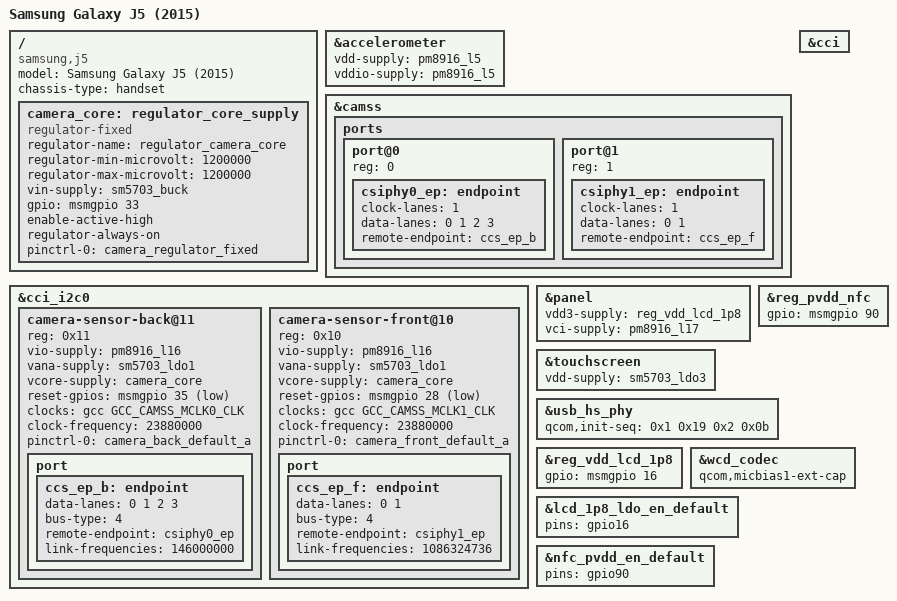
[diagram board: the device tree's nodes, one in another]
// SPDX-License-Identifier: GPL-2.0-only

/dts-v1/;

#include "msm8916-samsung-j5-common.dtsi"

/ {
	model = "Samsung Galaxy J5 (2015)";
	compatible = "samsung,j5", "qcom,msm8916";
	chassis-type = "handset";

	camera_core: regulator_core_supply {
		compatible = "regulator-fixed";
		regulator-name = "regulator_camera_core";
		regulator-min-microvolt = <1200000>;
		regulator-max-microvolt = <1200000>;

		vin-supply = <&sm5703_buck>;

		gpio = <&msmgpio 33 GPIO_ACTIVE_HIGH>;
		enable-active-high;
		regulator-always-on;

		pinctrl-names = "default";
		pinctrl-0 = <&camera_regulator_fixed>;
	};
};

&accelerometer {
	vdd-supply = <&pm8916_l5>;
	vddio-supply = <&pm8916_l5>;
};

&camss {
	status = "okay";

	ports {
		port@0 {
			reg = <0>;
			csiphy0_ep: endpoint {
				clock-lanes = <1>;
				data-lanes = <0 1 2 3>;
				remote-endpoint = <&ccs_ep_b>;
			};
		};
		port@1 {
			reg = <1>;
			csiphy1_ep: endpoint {
				clock-lanes = <1>;
				data-lanes = <0 1>;
				remote-endpoint = <&ccs_ep_f>;
			};
		};
	};
};

&cci {
	status = "okay";
};

// link-freq = width * height * bpp * fps / (2 * nlanes)

&cci_i2c0 {
	#address-cells = <1>;
	#size-cells = <0>;

	camera-sensor-back@11 {
		reg = <0x11>;
		// compatible = "mipi-ccs-1.0", "mipi-ccs";
		vio-supply = <&pm8916_l16>;
		vana-supply = <&sm5703_ldo1>;
		vcore-supply = <&camera_core>;
		reset-gpios = <&msmgpio 35 GPIO_ACTIVE_LOW>;
		clocks = <&gcc GCC_CAMSS_MCLK0_CLK>;
		clock-frequency = <23880000>;
		pinctrl-names = "default";
		pinctrl-0 = <&camera_back_default_a>;
		port {
			ccs_ep_b: endpoint {
				data-lanes = <0 1 2 3>;
				bus-type = <4>;
				remote-endpoint = <&csiphy0_ep>;
				link-frequencies = /bits/ 64 <146000000>;
			};
		};
	};

	camera-sensor-front@10 {
		reg = <0x10>;
		// compatible = "mipi-ccs-1.0", "mipi-ccs";
		vio-supply = <&pm8916_l16>;
		vana-supply = <&sm5703_ldo1>;
		vcore-supply = <&camera_core>;
		reset-gpios = <&msmgpio 28 GPIO_ACTIVE_LOW>;
		clocks = <&gcc GCC_CAMSS_MCLK1_CLK>;
		clock-frequency = <23880000>;
		pinctrl-names = "default";
		pinctrl-0 = <&camera_front_default_a>;
		port {
			ccs_ep_f: endpoint {
				data-lanes = <0 1>;
				bus-type = <4>;
				remote-endpoint = <&csiphy1_ep>; // 146MHz
				link-frequencies = /bits/ 64 <1086324736>;
			};
		};
	};
};

&panel {
	vdd3-supply = <&reg_vdd_lcd_1p8>;
	vci-supply = <&pm8916_l17>;
};

&reg_pvdd_nfc {
	gpio = <&msmgpio 90 GPIO_ACTIVE_HIGH>;
};

&touchscreen {
	vdd-supply = <&sm5703_ldo3>;
};

&usb_hs_phy {
	qcom,init-seq = /bits/ 8 <0x1 0x19 0x2 0x0b>;
};

&reg_vdd_lcd_1p8 {
	status = "okay";
	gpio = <&msmgpio 16 GPIO_ACTIVE_HIGH>;
};

&wcd_codec {
	qcom,micbias1-ext-cap;
};

&lcd_1p8_ldo_en_default {
	pins = "gpio16";
};

&nfc_pvdd_en_default {
	pins = "gpio90";
};
